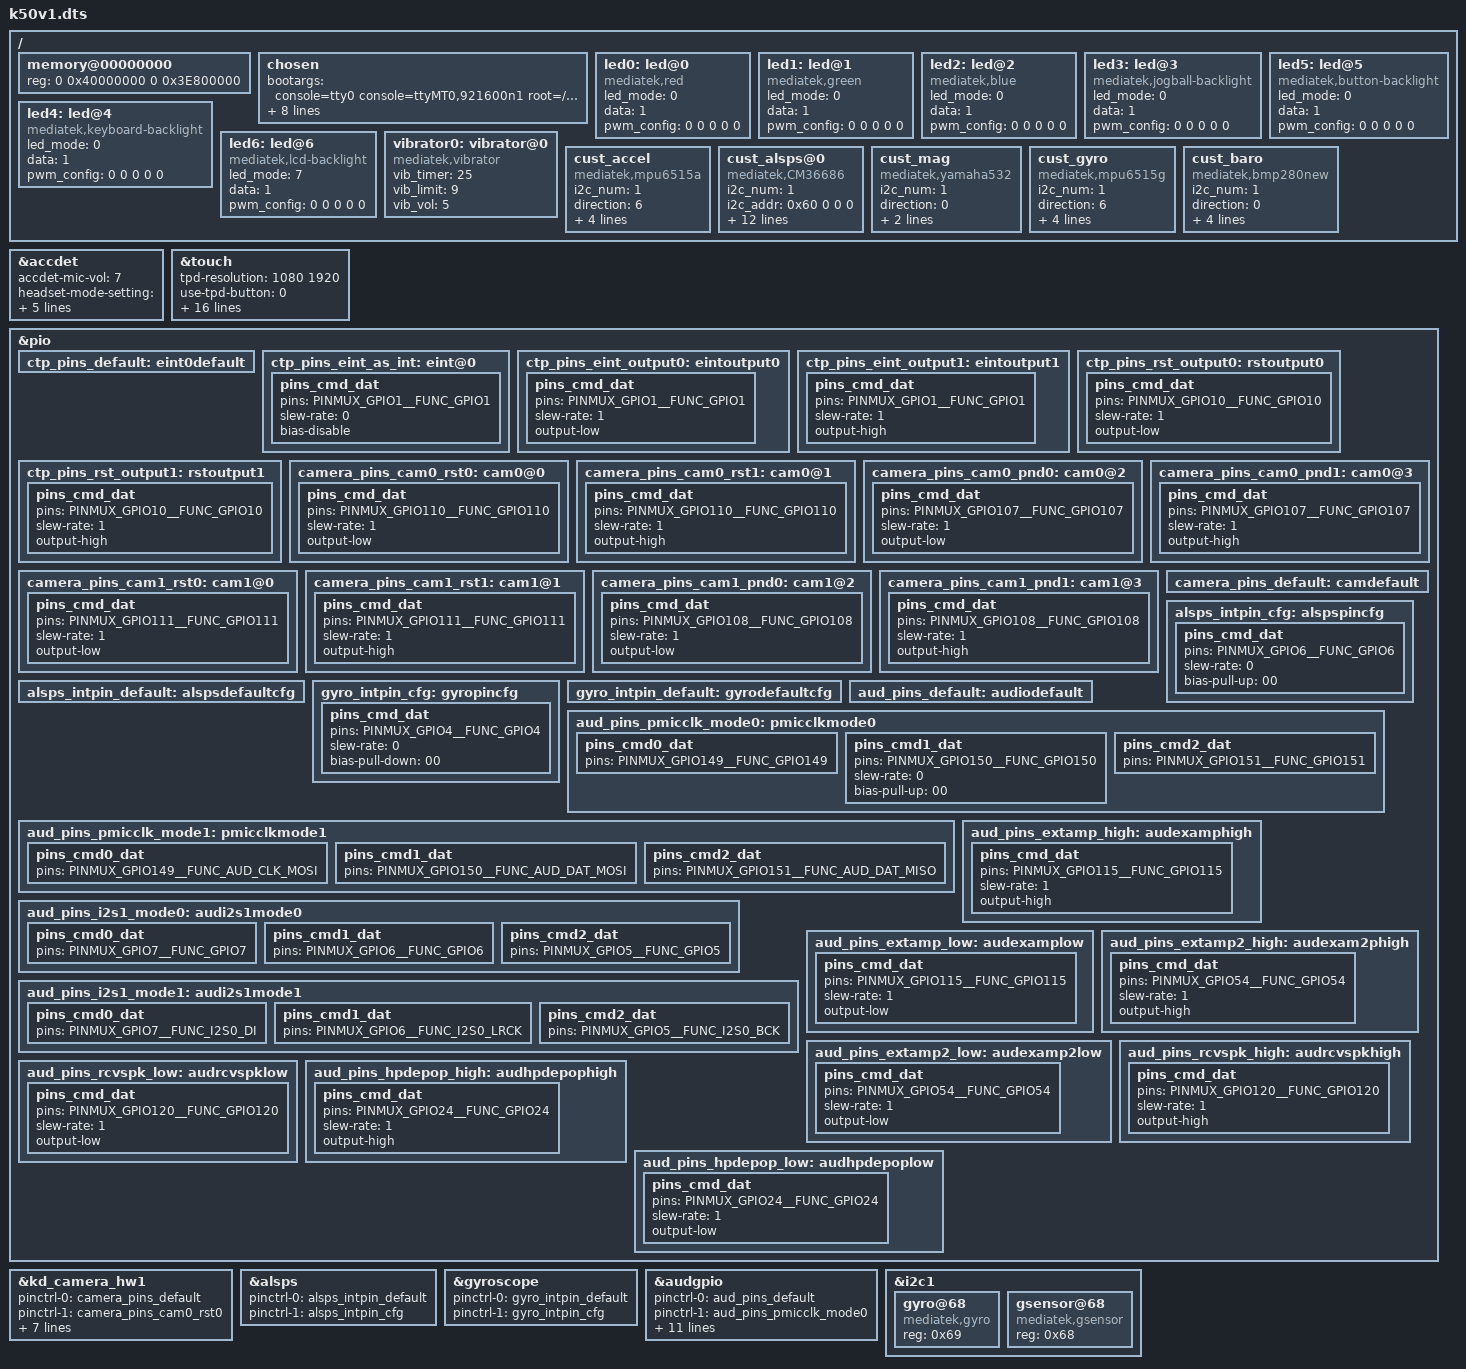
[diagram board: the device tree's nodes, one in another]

/dts-v1/;

#include "mt6755.dtsi"
#include "cust.dtsi"

/ {
	memory@00000000 {
		device_type = "memory";
		reg = <0 0x40000000 0 0x3E800000>;
	};
	/* chosen */
	chosen {
		bootargs = "console=tty0 console=ttyMT0,921600n1 root=/dev/ram initrd=0x44000000,0x4B434E loglevel=8";

		/* fpga may has no lk, we need to specify display info here */
		/* fb buffer is reserved using this dts by memory node above */
		atag,videolfb-fb_base_h = <0x0>;
		atag,videolfb-fb_base_l = <0x7E800000>;
		atag,videolfb-islcmfound = <1>;
		/* because no lk, so lcm is not inited */
		atag,videolfb-islcm_inited = <0>;
		atag,videolfb-fps= <6000>;
		atag,videolfb-vramSize= <0x01800000>;
		atag,videolfb-lcmname= "nt35695_fhd_dsi_cmd_truly_nt50358_drv";
	};
	led0:led@0 {
		compatible = "mediatek,red";
		led_mode = <0>;
		data = <1>;
		pwm_config = <0 0 0 0 0>;
	};
	led1:led@1 {
		compatible = "mediatek,green";
		led_mode = <0>;
		data = <1>;
		pwm_config = <0 0 0 0 0>;
	};
	led2:led@2 {
		compatible = "mediatek,blue";
		led_mode = <0>;
		data = <1>;
		pwm_config = <0 0 0 0 0>;
	};
	led3:led@3 {
		compatible = "mediatek,jogball-backlight";
		led_mode = <0>;
		data = <1>;
		pwm_config = <0 0 0 0 0>;
	};
	led4:led@4 {
		compatible = "mediatek,keyboard-backlight";
		led_mode = <0>;
		data = <1>;
		pwm_config = <0 0 0 0 0>;
	};
	led5:led@5 {
		compatible = "mediatek,button-backlight";
		led_mode = <0>;
		data = <1>;
		pwm_config = <0 0 0 0 0>;
	};
	led6:led@6 {
		compatible = "mediatek,lcd-backlight";
		led_mode = <7>;
		data = <1>;
		pwm_config = <0 0 0 0 0>;
	};
	vibrator0:vibrator@0 {
		compatible = "mediatek,vibrator";
		vib_timer = <25>;
		vib_limit = <9>;
		vib_vol= <5>;
	};
/*  start sensor */
	cust_accel {
		compatible = "mediatek,mpu6515a";
		i2c_num	= <1>;
		/* i2c_addr = <0x4c 0 0 0>; */
		direction = <6>;
		power_id = <0xffff>;
		power_vol = <0>;
		firlen = <16>;
		is_batch_supported = <1>;
	};

	cust_alsps@0 {
		compatible				= "mediatek,CM36686";
		i2c_num					= <1>;
		i2c_addr				= <0x60 0 0 0>;
		polling_mode_ps			= <0>;
		polling_mode_als		= <1>;
		power_id			= <0xffff>;
		power_vol			= <0>;
/* Total has 15 level*/
		als_level  = <0 471 1058 1703 3883 10171 10443 15445 28499 35153 41421 59194 65535 65535 65535>;
/*  Total has 16 range*/
		als_value  = <0 133 303 501 1002 2001 3355 5001 8008 10010 12000 16010 20010 20010 20010 20010>;
		ps_threshold_high		=  <70>;
		ps_threshold_low		=  <40>;
		is_batch_supported_ps	= <1>;
		is_batch_supported_als	= <1>;
	};

	cust_mag {
		compatible			= "mediatek,yamaha532";
		i2c_num				= <1>;
		/* i2c_addr			= <0x0d 0 0 0>; */
		direction			= <0>;
		power_id			= <0xffff>;
		power_vol			= <0>;
		/* is_batch_supported		= <0>; */
	};

	cust_gyro {
		compatible			= "mediatek,mpu6515g";
		i2c_num				= <1>;
		/* i2c_addr			= <0x68 0 0 0>; */
		direction			= <6>;
		power_id			= <0xffff>;
		power_vol			= <0>;
		firlen				= <0>;
		is_batch_supported		= <0>;
	};

	cust_baro {
		compatible			= "mediatek,bmp280new";
		i2c_num				= <1>;
		/* i2c_addr			= <0x68 0 0 0>; */
		direction			= <0>;
		power_id			= <0xffff>;
		power_vol			= <0>;
		firlen				= <32>;
		is_batch_supported		= <0>;
	};
/* end sensor */
};
&accdet {
	accdet-mic-vol = <7>;
	headset-mode-setting = <0x500 0x500 1 0x3F0 0x800 0x800 0x200>;
	accdet-plugout-debounce = <20>;
	/*1:ACC mode, 2:low cost without in bias, 6:low cost with in bias*/
	accdet-mic-mode = <1>;
	/*0--MD_MAX--UP_MAX--DW_MAX*/
	headset-three-key-threshold = <0 80 220 400>;
	/*0--MD_MAX--VOICE_MAX--UP_MAX--DW_MAX*/
	headset-four-key-threshold = <0 58 121 192 400>;
};

/* TOUCH start */
&touch {
	tpd-resolution = <1080 1920>;
	use-tpd-button = <0>;
	tpd-key-num = <3>;
	tpd-key-local= <139 172 158 0>;
	tpd-key-dim-local = <90 883 100 40 230 883 100 40 370 883 100 40 0 0 0 0>;
	tpd-max-touch-num = <5>;
	tpd-filter-enable = <1>;
	tpd-filter-pixel-density = <146>;
	tpd-filter-custom-prameters = <0 0 0 0 0 0 0 0 0 0 0 0>;
	tpd-filter-custom-speed = <0 0 0>;
	pinctrl-names = "default", "state_eint_as_int", "state_eint_output0", "state_eint_output1",
		"state_rst_output0", "state_rst_output1";
	pinctrl-0 = <&ctp_pins_default>;
	pinctrl-1 = <&ctp_pins_eint_as_int>;
	pinctrl-2 = <&ctp_pins_eint_output0>;
	pinctrl-3 = <&ctp_pins_eint_output1>;
	pinctrl-4 = <&ctp_pins_rst_output0>;
	pinctrl-5 = <&ctp_pins_rst_output1>;
	status = "okay";
};
&pio {
	ctp_pins_default: eint0default {
	};
	ctp_pins_eint_as_int: eint@0 {
		pins_cmd_dat {
			pins = <PINMUX_GPIO1__FUNC_GPIO1>;
			slew-rate = <0>;
			bias-disable;
		};
	};
	ctp_pins_eint_output0: eintoutput0 {
		pins_cmd_dat {
			pins = <PINMUX_GPIO1__FUNC_GPIO1>;
			slew-rate = <1>;
			output-low;
		};
	};
	ctp_pins_eint_output1: eintoutput1 {
		pins_cmd_dat {
			pins = <PINMUX_GPIO1__FUNC_GPIO1>;
			slew-rate = <1>;
			output-high;
		};
	};
	ctp_pins_rst_output0: rstoutput0 {
		pins_cmd_dat {
			pins = <PINMUX_GPIO10__FUNC_GPIO10>;
			slew-rate = <1>;
			output-low;
		};
	};
	ctp_pins_rst_output1: rstoutput1 {
		pins_cmd_dat {
			pins = <PINMUX_GPIO10__FUNC_GPIO10>;
			slew-rate = <1>;
			output-high;
		};
	};
};
/* TOUCH end */

/* CAMERA GPIO standardization */
&pio {
	camera_pins_cam0_rst0: cam0@0 {
		pins_cmd_dat {
			pins = <PINMUX_GPIO110__FUNC_GPIO110>;
			slew-rate = <1>; /*direction 0:in, 1:out*/
			output-low;/*direction out used only. output_low or high*/
		};
	};
	camera_pins_cam0_rst1: cam0@1 {
		pins_cmd_dat {
			pins = <PINMUX_GPIO110__FUNC_GPIO110>;
			slew-rate = <1>;
			output-high;
		};
	};
	camera_pins_cam0_pnd0: cam0@2 {
		pins_cmd_dat {
			pins = <PINMUX_GPIO107__FUNC_GPIO107>;
			slew-rate = <1>;
			output-low;
		};
	};
	camera_pins_cam0_pnd1: cam0@3 {
		pins_cmd_dat {
			pins = <PINMUX_GPIO107__FUNC_GPIO107>;
			slew-rate = <1>;
			output-high;
		};
	};
	camera_pins_cam1_rst0: cam1@0 {
		pins_cmd_dat {
			pins = <PINMUX_GPIO111__FUNC_GPIO111>;
			slew-rate = <1>; /*direction 0:in, 1:out*/
			output-low;/*direction out used only. output_low or high*/
		};
	};
	camera_pins_cam1_rst1: cam1@1 {
		pins_cmd_dat {
			pins = <PINMUX_GPIO111__FUNC_GPIO111>;
			slew-rate = <1>;
			output-high;
		};
	};
	camera_pins_cam1_pnd0: cam1@2 {
		pins_cmd_dat {
			pins = <PINMUX_GPIO108__FUNC_GPIO108>;
			slew-rate = <1>;
			output-low;
		};
	};
	camera_pins_cam1_pnd1: cam1@3 {
		pins_cmd_dat {
			pins = <PINMUX_GPIO108__FUNC_GPIO108>;
			slew-rate = <1>;
			output-high;
		};
	};
	/*camera_pins_cam_ldo_vcama_0: cam@vcama0 {
	};
	camera_pins_cam_ldo_vcama_1: cam@vcama1 {
	};*/
	camera_pins_default: camdefault {
	};

};

&kd_camera_hw1 {
	pinctrl-names = "default",
			"cam0_rst0", "cam0_rst1", "cam0_pnd0", "cam0_pnd1",
			"cam1_rst0", "cam1_rst1", "cam1_pnd0", "cam1_pnd1";
			/*"cam2_rst0", "cam2_rst1", "cam2_pnd0", "cam2_pnd1",
			"cam_ldo_vcama_0", "cam_ldo_vcama_1";*/
	pinctrl-0 = <&camera_pins_default>;
	pinctrl-1 = <&camera_pins_cam0_rst0>;
	pinctrl-2 = <&camera_pins_cam0_rst1>;
	pinctrl-3 = <&camera_pins_cam0_pnd0>;
	pinctrl-4 = <&camera_pins_cam0_pnd1>;
	pinctrl-5 = <&camera_pins_cam1_rst0>;
	pinctrl-6 = <&camera_pins_cam1_rst1>;
	pinctrl-7 = <&camera_pins_cam1_pnd0>;
	pinctrl-8 = <&camera_pins_cam1_pnd1>;
	/* for main2 */
	/*pinctrl-9 = <&camera_pins_cam2_rst0>;
	pinctrl-10 = <&camera_pins_cam2_rst1>;
	pinctrl-11 = <&camera_pins_cam2_pnd0>;
	pinctrl-12 = <&camera_pins_cam2_pnd1>;*/
	/* for ldo control by gpio */
	/*pinctrl-13 = <&camera_pins_cam_ldo_vcama_0>;
	pinctrl-14 = <&camera_pins_cam_ldo_vcama_1>;*/
	status = "okay";

};
/* CAMERA GPIO end */

&pio {
	alsps_intpin_cfg: alspspincfg {

		pins_cmd_dat {
			pins = <PINMUX_GPIO6__FUNC_GPIO6>;
			slew-rate = <0>;
			bias-pull-up = <00>;
		};
	};

	alsps_intpin_default: alspsdefaultcfg {

	};

	gyro_intpin_cfg: gyropincfg {

		pins_cmd_dat {
			pins = <PINMUX_GPIO4__FUNC_GPIO4>;
			slew-rate = <0>;
			bias-pull-down = <00>;
		};
	};

	gyro_intpin_default: gyrodefaultcfg {

	};
};

&alsps {
	pinctrl-names = "pin_default", "pin_cfg";
	pinctrl-0 = <&alsps_intpin_default>;
	pinctrl-1 = <&alsps_intpin_cfg>;
	status = "okay";
};

&gyroscope {
	pinctrl-names = "pin_default", "pin_cfg";
	pinctrl-0 = <&gyro_intpin_default>;
	pinctrl-1 = <&gyro_intpin_cfg>;
	status = "okay";
};

/* AUDIO GPIO standardization */
&audgpio {
	pinctrl-names = "default", "audpmicclk-mode0", "audpmicclk-mode1",
		"audi2s1-mode0", "audi2s1-mode1", "extamp-pullhigh", "extamp-pulllow",
		"extamp2-pullhigh", "extamp2-pulllow", "rcvspk-pullhigh",
		"rcvspk-pulllow","hpdepop-pullhigh","hpdepop-pulllow";
	pinctrl-0 = <&aud_pins_default>;
	pinctrl-1 = <&aud_pins_pmicclk_mode0>;
	pinctrl-2 = <&aud_pins_pmicclk_mode1>;
	pinctrl-3 = <&aud_pins_i2s1_mode0>;
	pinctrl-4 = <&aud_pins_i2s1_mode1>;
	pinctrl-5 = <&aud_pins_extamp_high>;
	pinctrl-6 = <&aud_pins_extamp_low>;
	pinctrl-7 = <&aud_pins_extamp2_high>;
	pinctrl-8 = <&aud_pins_extamp2_low>;
	pinctrl-9 = <&aud_pins_rcvspk_high>;
	pinctrl-10 = <&aud_pins_rcvspk_low>;
	pinctrl-11 = <&aud_pins_hpdepop_high>;
	pinctrl-12 = <&aud_pins_hpdepop_low>;
	status = "okay";
};

&pio {
	aud_pins_default: audiodefault {
	};

	aud_pins_pmicclk_mode0: pmicclkmode0 {
		pins_cmd0_dat {
			pins = <PINMUX_GPIO149__FUNC_GPIO149>;
		};
		pins_cmd1_dat {
			pins = <PINMUX_GPIO150__FUNC_GPIO150>;
			slew-rate = <0>;
			bias-pull-up = <00>;
		};
		pins_cmd2_dat {
			pins = <PINMUX_GPIO151__FUNC_GPIO151>;
		};
	};

	aud_pins_pmicclk_mode1: pmicclkmode1 {
		pins_cmd0_dat {
			pins = <PINMUX_GPIO149__FUNC_AUD_CLK_MOSI>;
		};
		pins_cmd1_dat {
			pins = <PINMUX_GPIO150__FUNC_AUD_DAT_MOSI>;
		};
		pins_cmd2_dat {
			pins = <PINMUX_GPIO151__FUNC_AUD_DAT_MISO>;
		};
	};

	aud_pins_i2s1_mode0: audi2s1mode0 {
		pins_cmd0_dat {
			pins = <PINMUX_GPIO7__FUNC_GPIO7>;
		};
		pins_cmd1_dat {
			pins = <PINMUX_GPIO6__FUNC_GPIO6>;
		};
		pins_cmd2_dat {
			pins = <PINMUX_GPIO5__FUNC_GPIO5>;
		};
	};

	aud_pins_i2s1_mode1: audi2s1mode1 {
		pins_cmd0_dat {
			pins = <PINMUX_GPIO7__FUNC_I2S0_DI>;
		};
		pins_cmd1_dat {
			pins = <PINMUX_GPIO6__FUNC_I2S0_LRCK>;
		};
		pins_cmd2_dat {
			pins = <PINMUX_GPIO5__FUNC_I2S0_BCK>;
		};
	};

	aud_pins_extamp_high: audexamphigh {
		pins_cmd_dat {
			pins = <PINMUX_GPIO115__FUNC_GPIO115>;
			slew-rate = <1>;
			output-high;
		};
	};

	aud_pins_extamp_low: audexamplow {
		pins_cmd_dat {
			pins = <PINMUX_GPIO115__FUNC_GPIO115>;
			slew-rate = <1>;
			output-low;
		};
	};

	aud_pins_extamp2_high: audexam2phigh {
		pins_cmd_dat {
			pins = <PINMUX_GPIO54__FUNC_GPIO54>;
			slew-rate = <1>;
			output-high;
		};
	};
	aud_pins_extamp2_low: audexamp2low {
		pins_cmd_dat {
			pins = <PINMUX_GPIO54__FUNC_GPIO54>;
			slew-rate = <1>;
			output-low;
		};
	};

	aud_pins_rcvspk_high: audrcvspkhigh {
		pins_cmd_dat {
			pins = <PINMUX_GPIO120__FUNC_GPIO120>;
			slew-rate = <1>;
			output-high;
		};
	};

	aud_pins_rcvspk_low: audrcvspklow {
		pins_cmd_dat {
			pins = <PINMUX_GPIO120__FUNC_GPIO120>;
			slew-rate = <1>;
			output-low;
		};
	};

	aud_pins_hpdepop_high: audhpdepophigh {
		pins_cmd_dat {
			pins = <PINMUX_GPIO24__FUNC_GPIO24>;
			slew-rate = <1>;
			output-high;
		};
	};

	aud_pins_hpdepop_low: audhpdepoplow {
		pins_cmd_dat {
			pins = <PINMUX_GPIO24__FUNC_GPIO24>;
			slew-rate = <1>;
			output-low;
		};
	};
};
/* AUDIO end */


&i2c1 {

	gyro@68 {
		compatible = "mediatek,gyro";
		reg = <0x69>;
		status = "okay";
	};

	gsensor@68 {
		compatible = "mediatek,gsensor";
		reg = <0x68>;
		status = "okay";
	};
};
